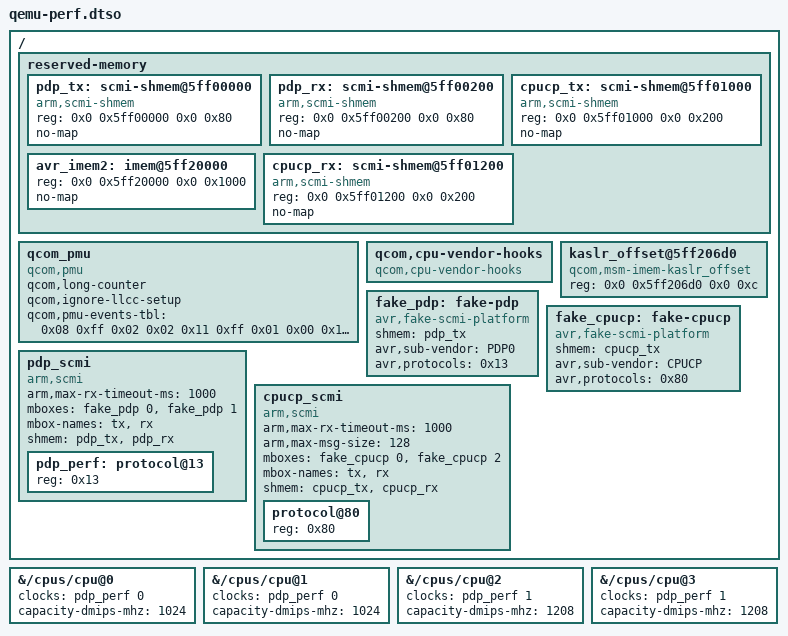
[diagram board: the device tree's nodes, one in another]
/dts-v1/;
/plugin/;
/* Private QEMU fixture: the Stage111 DVFS topology plus the phone's qcom,pmu
 * (pmu_lib), qcom,cpu-vendor-hooks, IMEM kaslr cell and the phone's
 * capacity-dmips-mhz (1024 silver, 1208 gold; needed for WALT topology init). DVFS part: pdp_scmi (perf 0x13,
 * sub-vendor PDP0) and cpucp_scmi (qcom vendor 0x80, sub-vendor CPUCP), each over
 * a mailbox (tx chan 0, rx chan 1/2) with the phone's shmem sizes (PDP 0x80,
 * CPUCP 0x200) and the avr73-fixups max-msg-size on CPUCP; CPUs reference
 * perf domains with clocks = <&perf N> (cluster0: domain 0, cluster1: domain 1).
 * The mailbox/firmware side is tests/qcom-cpucp-scmi/avr-fake-scmi.c. */
/ {
 fragment@0 { target-path="/"; __overlay__ {
  reserved-memory { #address-cells=<2>; #size-cells=<2>; ranges;
   pdp_tx: scmi-shmem@5ff00000 { compatible="arm,scmi-shmem"; reg=<0x0 0x5ff00000 0x0 0x80>; no-map; };
   pdp_rx: scmi-shmem@5ff00200 { compatible="arm,scmi-shmem"; reg=<0x0 0x5ff00200 0x0 0x80>; no-map; };
   cpucp_tx: scmi-shmem@5ff01000 { compatible="arm,scmi-shmem"; reg=<0x0 0x5ff01000 0x0 0x200>; no-map; };
   avr_imem2: imem@5ff20000 { reg=<0x0 0x5ff20000 0x0 0x1000>; no-map; };
   cpucp_rx: scmi-shmem@5ff01200 { compatible="arm,scmi-shmem"; reg=<0x0 0x5ff01200 0x0 0x200>; no-map; };
  };
  qcom_pmu { compatible="qcom,pmu"; qcom,long-counter; qcom,ignore-llcc-setup;
   qcom,pmu-events-tbl=<0x08 0xff 0x02 0x02 0x11 0xff 0x01 0x00 0x17 0xff 0xff 0x05 0x1000 0xff 0xff 0x08>; };
  qcom,cpu-vendor-hooks { compatible="qcom,cpu-vendor-hooks"; };
  kaslr_offset@5ff206d0 { compatible="qcom,msm-imem-kaslr_offset"; reg=<0x0 0x5ff206d0 0x0 0xc>; };
  fake_pdp: fake-pdp { compatible="avr,fake-scmi-platform"; #mbox-cells=<1>; shmem=<&pdp_tx>;
   avr,sub-vendor="PDP0"; avr,protocols=<0x13>; };
  fake_cpucp: fake-cpucp { compatible="avr,fake-scmi-platform"; #mbox-cells=<1>; shmem=<&cpucp_tx>;
   avr,sub-vendor="CPUCP"; avr,protocols=<0x80>; };
  pdp_scmi { compatible="arm,scmi"; #address-cells=<1>; #size-cells=<0>;
   arm,max-rx-timeout-ms=<1000>;	/* QEMU-only: TCG can stall the fake firmware > 30 ms */
   mboxes=<&fake_pdp 0 &fake_pdp 1>; mbox-names="tx","rx"; shmem=<&pdp_tx &pdp_rx>;
   pdp_perf: protocol@13 { reg=<0x13>; #clock-cells=<1>; }; };
  cpucp_scmi { compatible="arm,scmi"; #address-cells=<1>; #size-cells=<0>;
   arm,max-rx-timeout-ms=<1000>;	/* QEMU-only: TCG can stall the fake firmware > 30 ms */
   arm,max-msg-size=<128>;	/* ports/device-tree/avr73-fixups.dtso */
   mboxes=<&fake_cpucp 0 &fake_cpucp 2>; mbox-names="tx","rx"; shmem=<&cpucp_tx &cpucp_rx>;
   protocol@80 { reg=<0x80>; #clock-cells=<1>; }; };
 }; };
 fragment@1 { target-path="/cpus/cpu@0"; __overlay__ { clocks=<&pdp_perf 0>; capacity-dmips-mhz=<1024>; }; };
 fragment@2 { target-path="/cpus/cpu@1"; __overlay__ { clocks=<&pdp_perf 0>; capacity-dmips-mhz=<1024>; }; };
 fragment@3 { target-path="/cpus/cpu@2"; __overlay__ { clocks=<&pdp_perf 1>; capacity-dmips-mhz=<1208>; }; };
 fragment@4 { target-path="/cpus/cpu@3"; __overlay__ { clocks=<&pdp_perf 1>; capacity-dmips-mhz=<1208>; }; };
};
